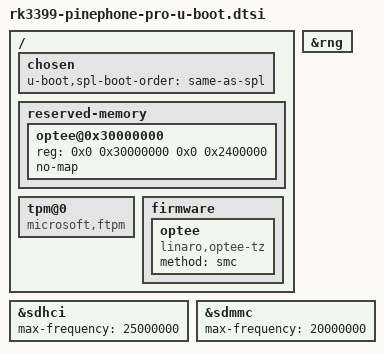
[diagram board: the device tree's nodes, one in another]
// SPDX-License-Identifier: GPL-2.0+
/*
 * Copyright (C) 2022 Peter Robinson <pbrobinson at gmail.com>
 */

#include "rk3399-u-boot.dtsi"
#include "rk3399-sdram-lpddr4-100.dtsi"

/ {
	chosen {
		u-boot,spl-boot-order = "same-as-spl", &sdhci, &sdmmc;

	};

	reserved-memory {
	        #address-cells = <2>;
	        #size-cells = <2>;
	        ranges;


	        optee@0x30000000 {
	                reg = <0x0 0x30000000 0x0 0x2400000>;
	                no-map;
	        };
	};

	tpm@0 {
		compatible = "microsoft,ftpm";
	};

	firmware {
		optee {
			compatible = "linaro,optee-tz";
			method = "smc";
		};
	};
};


&rng {
	status = "okay";
};

&sdhci {
	max-frequency = <25000000>;
	bootph-all;
};

&sdmmc {
	max-frequency = <20000000>;
	bootph-all;
};
